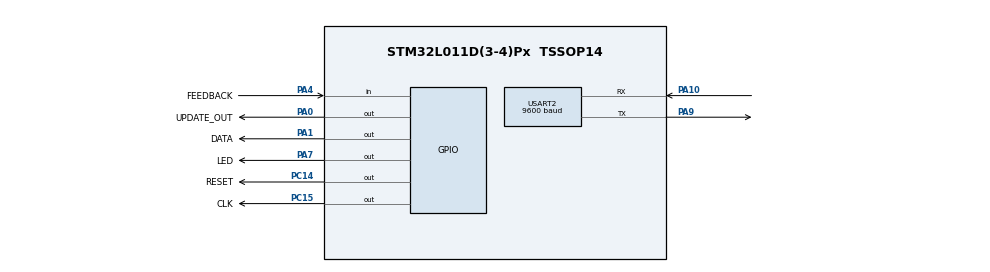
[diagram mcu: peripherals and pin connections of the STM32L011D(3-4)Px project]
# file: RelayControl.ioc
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Mcu.Family=STM32L0
Mcu.Name=STM32L011D(3-4)Px
Mcu.Package=TSSOP14
NVIC.USART2_IRQn=true\:0\:0\:false\:false\:true\:true\:false
PA0-CK_IN.GPIO_Label=UPDATE_OUT
PA0-CK_IN.Signal=GPIO_Output
PA1.GPIO_Label=DATA
PA1.Signal=GPIO_Output
PA10.Mode=Asynchronous
PA10.Signal=USART2_RX
PA13.Mode=Serial_Wire
PA13.Signal=SYS_SWDIO
PA14.Mode=Serial_Wire
PA14.Signal=SYS_SWCLK
PA4.GPIO_Label=FEEDBACK
PA4.Signal=GPIO_Input
PA7.GPIO_Label=LED
PA7.Signal=GPIO_Output
PA9.Mode=Asynchronous
PA9.Signal=USART2_TX
PC14-OSC32_IN.GPIO_Label=RESET
PC14-OSC32_IN.Signal=GPIO_Output
PC15-OSC32_OUT.GPIO_Label=CLK
PC15-OSC32_OUT.Signal=GPIO_Output
ProjectManager.HeapSize=0x200
ProjectManager.StackSize=0x200
ProjectManager.TargetToolchain=STM32CubeIDE
RCC.AHBFreq_Value=24000000
RCC.APB1Freq_Value=24000000
RCC.APB1TimFreq_Value=24000000
RCC.APB2Freq_Value=24000000
RCC.APB2TimFreq_Value=24000000
RCC.HCLKFreq_Value=24000000
RCC.HSE_VALUE=8000000
RCC.HSI16_VALUE=16000000
RCC.HSI_VALUE=16000000
RCC.LSE_VALUE=32768
RCC.MSI_VALUE=2097000
RCC.SYSCLKFreq_VALUE=24000000
RCC.SYSCLKSource=RCC_SYSCLKSOURCE_PLLCLK
RCC.VCOOutputFreq_Value=48000000
USART2.BaudRate=9600
USART2.Parity=PARITY_NONE
USART2.VirtualMode-Asynchronous=VM_ASYNC
USART2.WordLength=WORDLENGTH_8B
board=custom

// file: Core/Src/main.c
/* USER CODE BEGIN Header */
/**
  ******************************************************************************
  * @file           : main.c
  * @brief          : Main program body
  ******************************************************************************
  * @attention
  *
  * <h2><center>&copy; Copyright (c) 2021 STMicroelectronics.
  * All rights reserved.</center></h2>
  *
  * This software component is licensed by ST under BSD 3-Clause license,
  * the "License"; You may not use this file except in compliance with the
  * License. You may obtain a copy of the License at:
  *                        opensource.org/licenses/BSD-3-Clause
  *
  ******************************************************************************
  */
/* USER CODE END Header */
#include "main.h"
#include "usart.h"
#include "gpio.h"

/* USER CODE BEGIN Includes */
#include "Init.h"
/* USER CODE END Includes */

/* USER CODE BEGIN PM */
#define TOGGLE_LED()		LL_GPIO_TogglePin(LED_GPIO_Port, LED_Pin)
/* USER CODE END PM */

void SystemClock_Config(void);

int main(void)
{
  /* USER CODE BEGIN 1 */
	//unsigned long int counter= 0u;
  /* USER CODE END 1 */

  /* MCU Configuration--------------------------------------------------------*/

  /* Reset of all peripherals, Initializes the Flash interface and the Systick. */

  LL_APB2_GRP1_EnableClock(LL_APB2_GRP1_PERIPH_SYSCFG);
  LL_APB1_GRP1_EnableClock(LL_APB1_GRP1_PERIPH_PWR);

  /* System interrupt init*/

  /* Configure the system clock */
  SystemClock_Config();

  /* Initialize all configured peripherals */
  MX_GPIO_Init();
  MX_USART2_UART_Init();

  /* Infinite loop */
  /* USER CODE BEGIN WHILE */
  while (1)
  {
	  //for (counter = 0; counter < 2000000; counter++);
	  //TOGGLE_LED();
	  vInit();
    /* USER CODE END WHILE */

  }
}

void SystemClock_Config(void)
{
  LL_FLASH_SetLatency(LL_FLASH_LATENCY_1);
  while(LL_FLASH_GetLatency()!= LL_FLASH_LATENCY_1)
  {
  }
  LL_PWR_SetRegulVoltageScaling(LL_PWR_REGU_VOLTAGE_SCALE1);
  LL_RCC_HSI_Enable();

   /* Wait till HSI is ready */
  while(LL_RCC_HSI_IsReady() != 1)
  {

  }
  LL_RCC_HSI_SetCalibTrimming(16);
  LL_RCC_PLL_ConfigDomain_SYS(LL_RCC_PLLSOURCE_HSI, LL_RCC_PLL_MUL_3, LL_RCC_PLL_DIV_2);
  LL_RCC_PLL_Enable();

   /* Wait till PLL is ready */
  while(LL_RCC_PLL_IsReady() != 1)
  {

  }
  LL_RCC_SetAHBPrescaler(LL_RCC_SYSCLK_DIV_1);
  LL_RCC_SetAPB1Prescaler(LL_RCC_APB1_DIV_1);
  LL_RCC_SetAPB2Prescaler(LL_RCC_APB2_DIV_1);
  LL_RCC_SetSysClkSource(LL_RCC_SYS_CLKSOURCE_PLL);

   /* Wait till System clock is ready */
  while(LL_RCC_GetSysClkSource() != LL_RCC_SYS_CLKSOURCE_STATUS_PLL)
  {

  }

  LL_Init1msTick(24000000);

  LL_SetSystemCoreClock(24000000);
  LL_RCC_SetUSARTClockSource(LL_RCC_USART2_CLKSOURCE_PCLK1);
}

void Error_Handler(void)
{
  __disable_irq();
  while (1)
  {
  }
}

/************************ (C) COPYRIGHT STMicroelectronics *****END OF FILE****/
